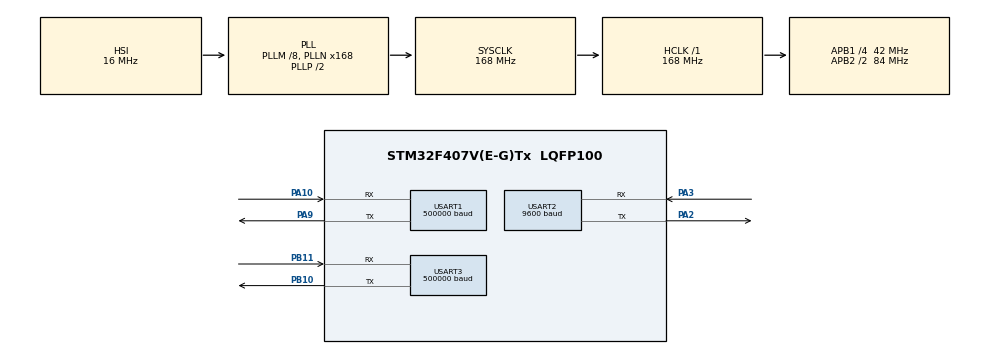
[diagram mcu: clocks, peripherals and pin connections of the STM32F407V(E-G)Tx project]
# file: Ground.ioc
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Dma.Request0=USART1_RX
Dma.Request1=USART1_TX
Dma.Request2=USART2_TX
Dma.Request3=USART2_RX
Dma.USART1_RX.0.Direction=DMA_PERIPH_TO_MEMORY
Dma.USART1_RX.0.FIFOMode=DMA_FIFOMODE_DISABLE
Dma.USART1_RX.0.Instance=DMA2_Stream2
Dma.USART1_RX.0.MemDataAlignment=DMA_MDATAALIGN_BYTE
Dma.USART1_RX.0.MemInc=DMA_MINC_ENABLE
Dma.USART1_RX.0.Mode=DMA_CIRCULAR
Dma.USART1_RX.0.PeriphDataAlignment=DMA_PDATAALIGN_BYTE
Dma.USART1_RX.0.PeriphInc=DMA_PINC_DISABLE
Dma.USART1_RX.0.Priority=DMA_PRIORITY_LOW
Dma.USART1_TX.1.Direction=DMA_MEMORY_TO_PERIPH
Dma.USART1_TX.1.FIFOMode=DMA_FIFOMODE_DISABLE
Dma.USART1_TX.1.Instance=DMA2_Stream7
Dma.USART1_TX.1.MemDataAlignment=DMA_MDATAALIGN_BYTE
Dma.USART1_TX.1.MemInc=DMA_MINC_ENABLE
Dma.USART1_TX.1.Mode=DMA_NORMAL
Dma.USART1_TX.1.PeriphDataAlignment=DMA_PDATAALIGN_BYTE
Dma.USART1_TX.1.PeriphInc=DMA_PINC_DISABLE
Dma.USART1_TX.1.Priority=DMA_PRIORITY_LOW
Dma.USART2_RX.3.Direction=DMA_PERIPH_TO_MEMORY
Dma.USART2_RX.3.FIFOMode=DMA_FIFOMODE_DISABLE
Dma.USART2_RX.3.Instance=DMA1_Stream5
Dma.USART2_RX.3.MemDataAlignment=DMA_MDATAALIGN_BYTE
Dma.USART2_RX.3.MemInc=DMA_MINC_ENABLE
Dma.USART2_RX.3.Mode=DMA_CIRCULAR
Dma.USART2_RX.3.PeriphDataAlignment=DMA_PDATAALIGN_BYTE
Dma.USART2_RX.3.PeriphInc=DMA_PINC_DISABLE
Dma.USART2_RX.3.Priority=DMA_PRIORITY_LOW
Dma.USART2_TX.2.Direction=DMA_MEMORY_TO_PERIPH
Dma.USART2_TX.2.FIFOMode=DMA_FIFOMODE_DISABLE
Dma.USART2_TX.2.Instance=DMA1_Stream6
Dma.USART2_TX.2.MemDataAlignment=DMA_MDATAALIGN_BYTE
Dma.USART2_TX.2.MemInc=DMA_MINC_ENABLE
Dma.USART2_TX.2.Mode=DMA_NORMAL
Dma.USART2_TX.2.PeriphDataAlignment=DMA_PDATAALIGN_BYTE
Dma.USART2_TX.2.PeriphInc=DMA_PINC_DISABLE
Dma.USART2_TX.2.Priority=DMA_PRIORITY_LOW
FREERTOS.Tasks01=Task_LX,40,1024,APPTask_LX,As weak,NULL,Dynamic,NULL,NULL;Ground_UART,24,256,Ground_DT_UART,As weak,NULL,Dynamic,NULL,NULL;UART_Touch,24,256,UART_DT_Touch,As weak,NULL,Dynamic,NULL,NULL
FREERTOS.configTOTAL_HEAP_SIZE=32768
Mcu.Family=STM32F4
Mcu.Name=STM32F407V(E-G)Tx
Mcu.Package=LQFP100
NVIC.DMA1_Stream5_IRQn=true\:5\:0\:false\:false\:true\:true\:false\:true\:true
NVIC.DMA1_Stream6_IRQn=true\:5\:0\:false\:false\:true\:true\:false\:true\:true
NVIC.DMA2_Stream2_IRQn=true\:5\:0\:false\:false\:true\:true\:false\:true\:true
NVIC.DMA2_Stream7_IRQn=true\:5\:0\:false\:false\:true\:true\:false\:true\:true
NVIC.PriorityGroup=NVIC_PRIORITYGROUP_4
NVIC.TIM1_UP_TIM10_IRQn=true\:5\:0\:false\:false\:true\:true\:true\:true\:true
NVIC.TIM8_TRG_COM_TIM14_IRQn=true\:15\:0\:false\:false\:true\:false\:false\:true\:true
NVIC.TimeBase=TIM8_TRG_COM_TIM14_IRQn
NVIC.TimeBaseIP=TIM14
NVIC.USART1_IRQn=true\:5\:0\:false\:false\:true\:true\:true\:true\:true
NVIC.USART2_IRQn=true\:5\:0\:false\:false\:true\:true\:true\:true\:true
NVIC.USART3_IRQn=true\:5\:0\:false\:false\:true\:true\:true\:true\:true
PA10.Mode=Asynchronous
PA10.Signal=USART1_RX
PA13.Mode=Serial_Wire
PA13.Signal=SYS_JTMS-SWDIO
PA14.Mode=Serial_Wire
PA14.Signal=SYS_JTCK-SWCLK
PA2.Mode=Asynchronous
PA2.Signal=USART2_TX
PA3.Mode=Asynchronous
PA3.Signal=USART2_RX
PA9.Mode=Asynchronous
PA9.Signal=USART1_TX
PB10.Mode=Asynchronous
PB10.Signal=USART3_TX
PB11.Mode=Asynchronous
PB11.Signal=USART3_RX
PH0-OSC_IN.Mode=HSE-External-Oscillator
PH0-OSC_IN.Signal=RCC_OSC_IN
PH1-OSC_OUT.Mode=HSE-External-Oscillator
PH1-OSC_OUT.Signal=RCC_OSC_OUT
ProjectManager.HeapSize=0x200
ProjectManager.StackSize=0x400
ProjectManager.TargetToolchain=MDK-ARM V5.32
RCC.48MHZClocksFreq_Value=84000000
RCC.AHBFreq_Value=168000000
RCC.APB1CLKDivider=RCC_HCLK_DIV4
RCC.APB1Freq_Value=42000000
RCC.APB1TimFreq_Value=84000000
RCC.APB2CLKDivider=RCC_HCLK_DIV2
RCC.APB2Freq_Value=84000000
RCC.APB2TimFreq_Value=168000000
RCC.CortexFreq_Value=168000000
RCC.HCLKFreq_Value=168000000
RCC.HSE_VALUE=25000000
RCC.HSI_VALUE=16000000
RCC.LSE_VALUE=32768
RCC.PLLM=8
RCC.PLLN=168
RCC.SYSCLKFreq_VALUE=168000000
RCC.SYSCLKSource=RCC_SYSCLKSOURCE_PLLCLK
RCC.VCOOutputFreq_Value=336000000
TIM1.Period=100-1
TIM1.Prescaler=1680-1
USART1.BaudRate=500000
USART1.VirtualMode=VM_ASYNC
USART2.BaudRate=9600
USART2.VirtualMode=VM_ASYNC
USART3.BaudRate=500000
USART3.VirtualMode=VM_ASYNC
VP_FREERTOS_VS_CMSIS_V2.Mode=CMSIS_V2
VP_SYS_VS_tim14.Mode=TIM14
VP_TIM1_VS_ClockSourceINT.Mode=Internal
board=custom

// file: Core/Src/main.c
/* USER CODE BEGIN Header */
/**
  ******************************************************************************
  * @file           : main.c
  * @brief          : Main program body
  ******************************************************************************
  * @attention
  *
  * Copyright (c) 2026 STMicroelectronics.
  * All rights reserved.
  *
  * This software is licensed under terms that can be found in the LICENSE file
  * in the root directory of this software component.
  * If no LICENSE file comes with this software, it is provided AS-IS.
  *
  ******************************************************************************
  */
/* USER CODE END Header */
#include "main.h"
#include "cmsis_os.h"
#include "dma.h"
#include "tim.h"
#include "usart.h"
#include "gpio.h"

/* USER CODE BEGIN Includes */
#include "driver_registry.h"
/* USER CODE END Includes */

void SystemClock_Config(void);
void MX_FREERTOS_Init(void);

/* USER CODE BEGIN 0 */
extern osThreadId_t Task_LXHandle;
/* USER CODE END 0 */

int main(void)
{

  /* MCU Configuration--------------------------------------------------------*/

  /* Reset of all peripherals, Initializes the Flash interface and the Systick. */
  HAL_Init();

  /* Configure the system clock */
  SystemClock_Config();

  /* Initialize all configured peripherals */
  MX_GPIO_Init();
  MX_DMA_Init();
  MX_TIM1_Init();
  MX_USART1_UART_Init();
  MX_USART2_UART_Init();
  MX_USART3_UART_Init();
  /* USER CODE BEGIN 2 */

  /* 启动 TIM1 更新中断（1ms 周期，用于通知 LX 调度任务） */
  HAL_TIM_Base_Start_IT(&htim1);

  /* USER CODE END 2 */

  /* Init scheduler */
  osKernelInitialize();  /* Call init function for freertos objects (in cmsis_os2.c) */
  MX_FREERTOS_Init();

  /* Start scheduler */
  osKernelStart();

  /* We should never get here as control is now taken by the scheduler */

  /* Infinite loop */
  while (1)
  {

  }
}

void SystemClock_Config(void)
{
  RCC_OscInitTypeDef RCC_OscInitStruct = {0};
  RCC_ClkInitTypeDef RCC_ClkInitStruct = {0};

  /** Configure the main internal regulator output voltage
  */
  __HAL_RCC_PWR_CLK_ENABLE();
  __HAL_PWR_VOLTAGESCALING_CONFIG(PWR_REGULATOR_VOLTAGE_SCALE1);

  /** Initializes the RCC Oscillators according to the specified parameters
  * in the RCC_OscInitTypeDef structure.
  */
  RCC_OscInitStruct.OscillatorType = RCC_OSCILLATORTYPE_HSI;
  RCC_OscInitStruct.HSIState = RCC_HSI_ON;
  RCC_OscInitStruct.HSICalibrationValue = RCC_HSICALIBRATION_DEFAULT;
  RCC_OscInitStruct.PLL.PLLState = RCC_PLL_ON;
  RCC_OscInitStruct.PLL.PLLSource = RCC_PLLSOURCE_HSI;
  RCC_OscInitStruct.PLL.PLLM = 8;
  RCC_OscInitStruct.PLL.PLLN = 168;
  RCC_OscInitStruct.PLL.PLLP = RCC_PLLP_DIV2;
  RCC_OscInitStruct.PLL.PLLQ = 4;
  if (HAL_RCC_OscConfig(&RCC_OscInitStruct) != HAL_OK)
  {
    Error_Handler();
  }

  /** Initializes the CPU, AHB and APB buses clocks
  */
  RCC_ClkInitStruct.ClockType = RCC_CLOCKTYPE_HCLK|RCC_CLOCKTYPE_SYSCLK
                              |RCC_CLOCKTYPE_PCLK1|RCC_CLOCKTYPE_PCLK2;
  RCC_ClkInitStruct.SYSCLKSource = RCC_SYSCLKSOURCE_PLLCLK;
  RCC_ClkInitStruct.AHBCLKDivider = RCC_SYSCLK_DIV1;
  RCC_ClkInitStruct.APB1CLKDivider = RCC_HCLK_DIV4;
  RCC_ClkInitStruct.APB2CLKDivider = RCC_HCLK_DIV2;

  if (HAL_RCC_ClockConfig(&RCC_ClkInitStruct, FLASH_LATENCY_5) != HAL_OK)
  {
    Error_Handler();
  }
}

void HAL_TIM_PeriodElapsedCallback(TIM_HandleTypeDef *htim)
{
  if (htim->Instance == TIM14)
  {
    HAL_IncTick();
  }
  /* USER CODE BEGIN Callback 1 */
  if (htim == &htim1)
  {
    if (Task_LXHandle != NULL)
      {
          BaseType_t highTaskWoken = pdFALSE;
          vTaskNotifyGiveFromISR(Task_LXHandle,&highTaskWoken);
          portYIELD_FROM_ISR(highTaskWoken);   // 保证高优先级的能够抢占
      }
  }

  /* USER CODE END Callback 1 */
}

void Error_Handler(void)
{
  __disable_irq();
  while (1)
  {
  }
}

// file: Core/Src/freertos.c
/* USER CODE BEGIN Header */
/**
  ******************************************************************************
  * File Name          : freertos.c
  * Description        : Code for freertos applications
  ******************************************************************************
  * @attention
  *
  * Copyright (c) 2026 STMicroelectronics.
  * All rights reserved.
  *
  * This software is licensed under terms that can be found in the LICENSE file
  * in the root directory of this software component.
  * If no LICENSE file comes with this software, it is provided AS-IS.
  *
  ******************************************************************************
  */
/* USER CODE END Header */

#include "FreeRTOS.h"
#include "task.h"
#include "main.h"
#include "cmsis_os.h"

/* Definitions for Task_LX */
osThreadId_t Task_LXHandle;
const osThreadAttr_t Task_LX_attributes = {
  .name = "Task_LX",
  .stack_size = 1024 * 4,
  .priority = (osPriority_t) osPriorityHigh,
};
/* Definitions for Ground_UART */
osThreadId_t Ground_UARTHandle;
const osThreadAttr_t Ground_UART_attributes = {
  .name = "Ground_UART",
  .stack_size = 256 * 4,
  .priority = (osPriority_t) osPriorityNormal,
};
/* Definitions for UART_Touch */
osThreadId_t UART_TouchHandle;
const osThreadAttr_t UART_Touch_attributes = {
  .name = "UART_Touch",
  .stack_size = 256 * 4,
  .priority = (osPriority_t) osPriorityNormal,
};

void APPTask_LX(void *argument);
void Ground_DT_UART(void *argument);
void UART_DT_Touch(void *argument);

void MX_FREERTOS_Init(void); /* (MISRA C 2004 rule 8.1) */

void MX_FREERTOS_Init(void) {

  /* Create the thread(s) */
  /* creation of Task_LX */
  Task_LXHandle = osThreadNew(APPTask_LX, NULL, &Task_LX_attributes);

  /* creation of Ground_UART */
  Ground_UARTHandle = osThreadNew(Ground_DT_UART, NULL, &Ground_UART_attributes);

  /* creation of UART_Touch */
  UART_TouchHandle = osThreadNew(UART_DT_Touch, NULL, &UART_Touch_attributes);

}

__weak void APPTask_LX(void *argument)
{
  for(;;)
  {
    osDelay(1);
  }
}

__weak void Ground_DT_UART(void *argument)
{
  for(;;)
  {
    osDelay(1);
  }
}

__weak void UART_DT_Touch(void *argument)
{
  for(;;)
  {
    osDelay(1);
  }
}
